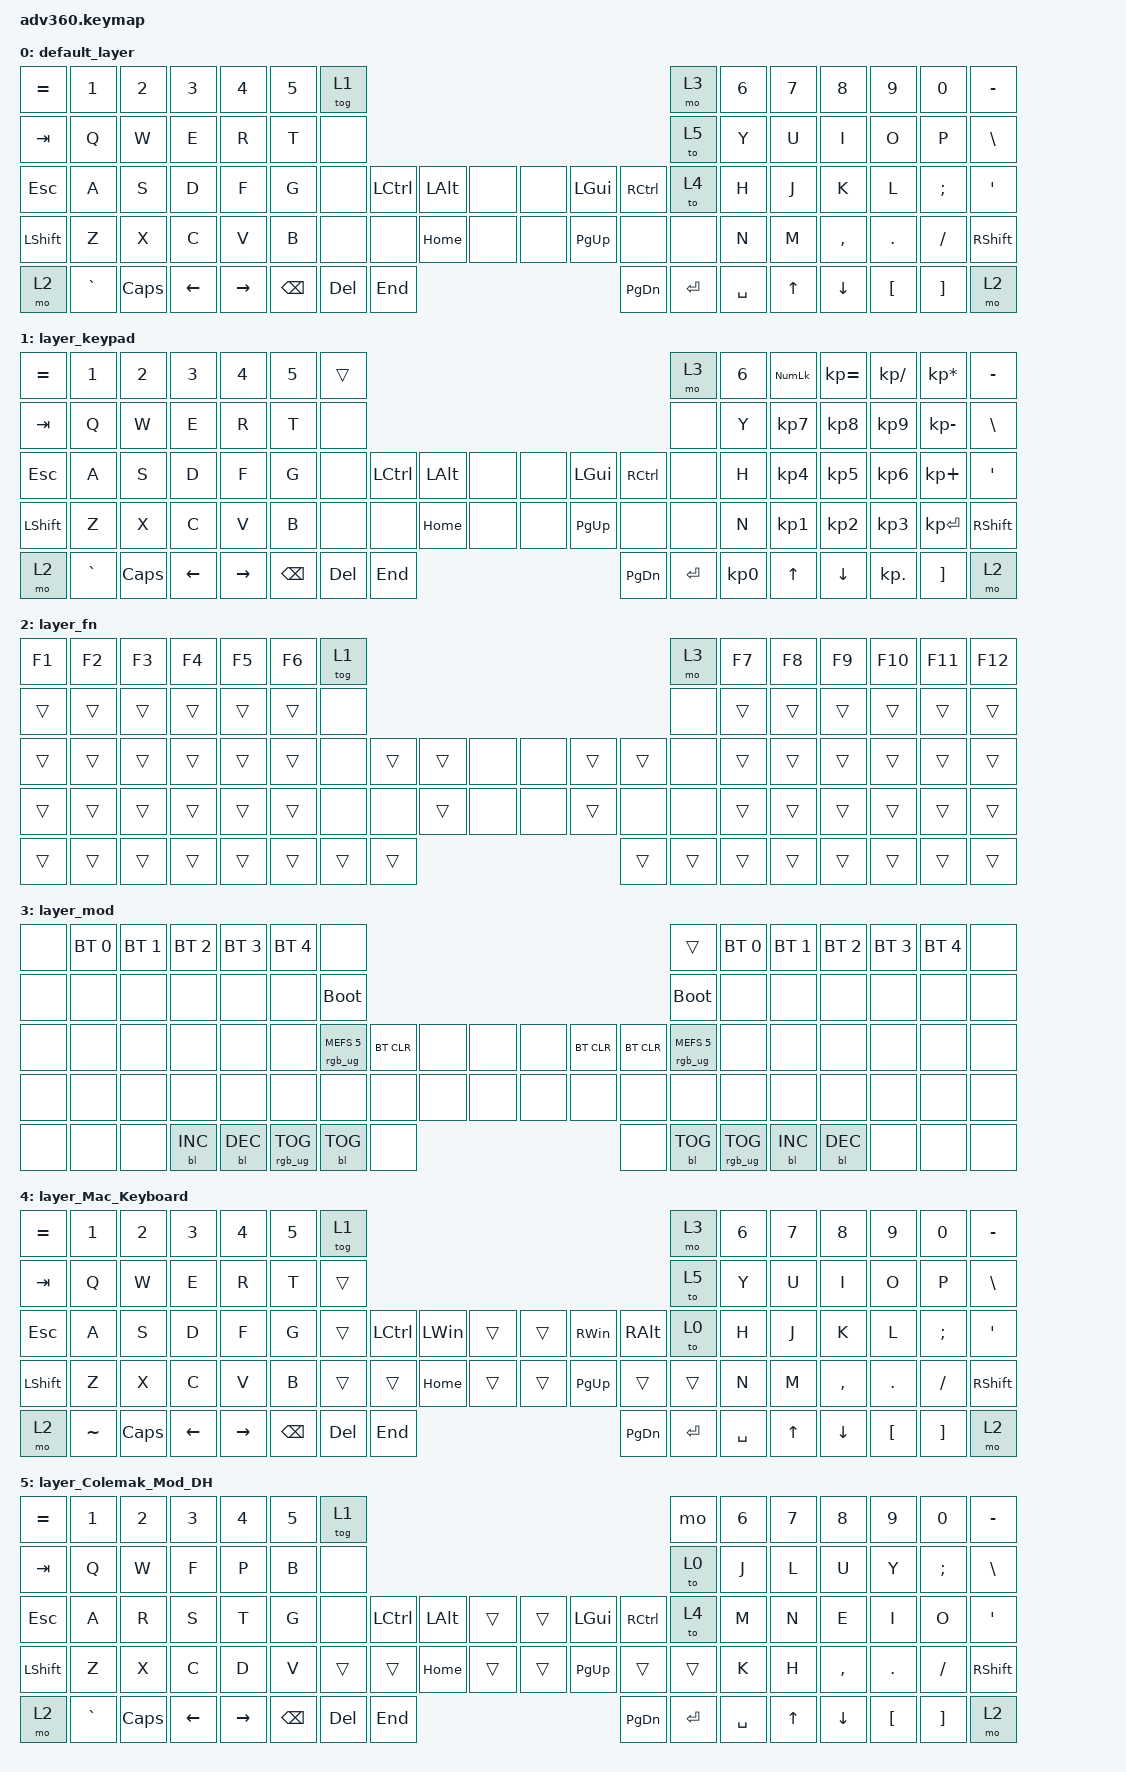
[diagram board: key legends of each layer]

/*
 * Copyright (c) 2020 The ZMK Contributors
 *
 * SPDX-License-Identifier: MIT
 */


/* THIS FILE WAS GENERATED!
 *
 * This file was generated automatically. You may or may not want to
 * edit it directly.
 */

#include <behaviors.dtsi>
#include <dt-bindings/zmk/keys.h>
#include <dt-bindings/zmk/bt.h>
#include <dt-bindings/zmk/rgb.h>
#include <dt-bindings/zmk/backlight.h>

/ {
  behaviors {
    #include "macros.dtsi"
    #include "version.dtsi"

    hm: homerow_mods {
        compatible = "zmk,behavior-hold-tap";
        label = "HOMEROW_MODS";
        #binding-cells = <2>;
        tapping-term-ms = <200>;
        quick_tap_ms = <175>;
        flavor = "tap-preferred";
        bindings = <&kp>, <&kp>;
    };
  };

    keymap {
        compatible = "zmk,keymap";


        default_layer {
            bindings = <
 &kp EQUAL     &kp N1    &kp N2    &kp N3     &kp N4  &kp N5              &tog 1                                                                 &mo 3  &kp N6  &kp N7     &kp N8    &kp N9    &kp N0  &kp MINUS
   &kp TAB      &kp Q     &kp W     &kp E      &kp R   &kp T               &none                                                                 &to 5   &kp Y   &kp U      &kp I     &kp O     &kp P   &kp BSLH
   &kp ESC      &kp A     &kp S     &kp D      &kp F   &kp G               &none  &kp LCTRL  &kp LALT   &none   &none   &kp LGUI  &kp RCTRL      &to 4   &kp H   &kp J      &kp K     &kp L  &kp SEMI    &kp SQT
 &kp LSHFT      &kp Z     &kp X     &kp C      &kp V   &kp B               &none      &none  &kp HOME   &none   &none  &kp PG_UP      &none      &none   &kp N   &kp M  &kp COMMA   &kp DOT  &kp FSLH  &kp RSHFT
     &mo 2  &kp GRAVE  &kp CAPS  &kp LEFT  &kp RIGHT                    &kp BSPC    &kp DEL   &kp END                  &kp PG_DN  &kp ENTER  &kp SPACE          &kp UP   &kp DOWN  &kp LBKT  &kp RBKT      &mo 2
            >;
        };

        layer_keypad {
            bindings = <
 &kp EQUAL     &kp N1    &kp N2    &kp N3     &kp N4  &kp N5              &trans                                                                 &mo 3  &kp N6  &kp KP_NUM  &kp KP_EQUAL  &kp KP_DIVIDE  &kp KP_MULTIPLY  &kp MINUS
   &kp TAB      &kp Q     &kp W     &kp E      &kp R   &kp T               &none                                                                 &none   &kp Y   &kp KP_N7     &kp KP_N8      &kp KP_N9     &kp KP_MINUS   &kp BSLH
   &kp ESC      &kp A     &kp S     &kp D      &kp F   &kp G               &none  &kp LCTRL  &kp LALT   &none   &none   &kp LGUI  &kp RCTRL      &none   &kp H   &kp KP_N4     &kp KP_N5      &kp KP_N6      &kp KP_PLUS    &kp SQT
 &kp LSHFT      &kp Z     &kp X     &kp C      &kp V   &kp B               &none      &none  &kp HOME   &none   &none  &kp PG_UP      &none      &none   &kp N   &kp KP_N1     &kp KP_N2      &kp KP_N3     &kp KP_ENTER  &kp RSHFT
     &mo 2  &kp GRAVE  &kp CAPS  &kp LEFT  &kp RIGHT                    &kp BSPC    &kp DEL   &kp END                  &kp PG_DN  &kp ENTER  &kp KP_N0              &kp UP      &kp DOWN     &kp KP_DOT         &kp RBKT      &mo 2
            >;
        };

        layer_fn {
            bindings = <
 &kp F1  &kp F2  &kp F3  &kp F4  &kp F5  &kp F6            &tog 1                                                   &mo 3  &kp F7  &kp F8  &kp F9  &kp F10  &kp F11  &kp F12
 &trans  &trans  &trans  &trans  &trans  &trans             &none                                                   &none  &trans  &trans  &trans   &trans   &trans   &trans
 &trans  &trans  &trans  &trans  &trans  &trans             &none  &trans  &trans   &none   &none  &trans  &trans   &none  &trans  &trans  &trans   &trans   &trans   &trans
 &trans  &trans  &trans  &trans  &trans  &trans             &none   &none  &trans   &none   &none  &trans   &none   &none  &trans  &trans  &trans   &trans   &trans   &trans
 &trans  &trans  &trans  &trans  &trans                    &trans  &trans  &trans                  &trans  &trans  &trans          &trans  &trans   &trans   &trans   &trans
            >;
        };

        layer_mod {
            bindings = <
  &none  &bt BT_SEL 0  &bt BT_SEL 1  &bt BT_SEL 2  &bt BT_SEL 3  &bt BT_SEL 4                             &none                                                                              &trans  &bt BT_SEL 0  &bt BT_SEL 1  &bt BT_SEL 2  &bt BT_SEL 3  &bt BT_SEL 4   &none
  &none         &none         &none         &none         &none         &none                       &bootloader                                                                         &bootloader         &none         &none         &none         &none         &none   &none
  &none         &none         &none         &none         &none         &none            &rgb_ug RGB_MEFS_CMD 5  &bt BT_CLR   &none   &none   &none  &bt BT_CLR  &bt BT_CLR  &rgb_ug RGB_MEFS_CMD 5         &none         &none         &none         &none         &none   &none
  &none         &none         &none         &none         &none         &none                             &none       &none   &none   &none   &none       &none       &none                   &none         &none         &none         &none         &none         &none   &none
  &none         &none         &none    &bl BL_INC    &bl BL_DEC                                 &rgb_ug RGB_TOG  &bl BL_TOG   &none                       &none  &bl BL_TOG         &rgb_ug RGB_TOG                  &bl BL_INC    &bl BL_DEC         &none         &none   &none
            >;
        };

        layer_Mac_Keyboard {
            bindings = <
      &kp EQUAL  &kp NUMBER_1  &kp NUMBER_2    &kp NUMBER_3     &kp NUMBER_4  &kp NUMBER_5                   &tog 1                                                                              &mo 3  &kp NUMBER_6  &kp NUMBER_7    &kp NUMBER_8      &kp NUMBER_9       &kp NUMBER_0         &kp MINUS
        &kp TAB         &kp Q         &kp W           &kp E            &kp R         &kp T                   &trans                                                                              &to 5         &kp Y         &kp U           &kp I             &kp O              &kp P     &kp BACKSLASH
        &kp ESC         &kp A         &kp S           &kp D            &kp F         &kp G                   &trans   &kp LCTRL  &kp LEFT_WIN  &trans  &trans       &kp RWIN  &kp RIGHT_ALT      &to 0         &kp H         &kp J           &kp K             &kp L      &kp SEMICOLON  &kp SINGLE_QUOTE
 &kp LEFT_SHIFT         &kp Z         &kp X           &kp C            &kp V         &kp B                   &trans      &trans      &kp HOME  &trans  &trans    &kp PAGE_UP         &trans     &trans         &kp N         &kp M       &kp COMMA        &kp PERIOD          &kp SLASH   &kp RIGHT_SHIFT
          &mo 2     &kp TILDE  &kp CAPSLOCK  &kp LEFT_ARROW  &kp RIGHT_ARROW                          &kp BACKSPACE  &kp DELETE       &kp END                  &kp PAGE_DOWN      &kp ENTER  &kp SPACE                &kp UP_ARROW  &kp DOWN_ARROW  &kp LEFT_BRACKET  &kp RIGHT_BRACKET             &mo 2
            >;
        };

        layer_Colemak_Mod_DH {
            bindings = <
      &kp EQUAL  &kp NUMBER_1    &kp N2          &kp N3           &kp N4  &kp N5                   &tog 1                                                                                  &mo  &kp N6        &kp N7          &kp N8            &kp N9             &kp N0         &kp MINUS
        &kp TAB         &kp Q     &kp W           &kp F            &kp P   &kp B                    &none                                                                                &to 0   &kp J         &kp L           &kp U             &kp Y           &kp SEMI     &kp BACKSLASH
        &kp ESC         &kp A     &kp R           &kp S            &kp T   &kp G                    &none  &kp LEFT_CONTROL  &kp LEFT_ALT  &trans  &trans       &kp LGUI  &kp RCTRL      &to 4   &kp M         &kp N           &kp E             &kp I              &kp O  &kp SINGLE_QUOTE
 &kp LEFT_SHIFT         &kp Z     &kp X           &kp C            &kp D   &kp V                   &trans            &trans      &kp HOME  &trans  &trans    &kp PAGE_UP     &trans     &trans   &kp K         &kp H       &kp COMMA        &kp PERIOD          &kp SLASH   &kp RIGHT_SHIFT
          &mo 2     &kp GRAVE  &kp CAPS  &kp LEFT_ARROW  &kp RIGHT_ARROW                    &kp BACKSPACE        &kp DELETE       &kp END                  &kp PAGE_DOWN  &kp ENTER  &kp SPACE          &kp UP_ARROW  &kp DOWN_ARROW  &kp LEFT_BRACKET  &kp RIGHT_BRACKET             &mo 2
            >;
        };

    };
};
